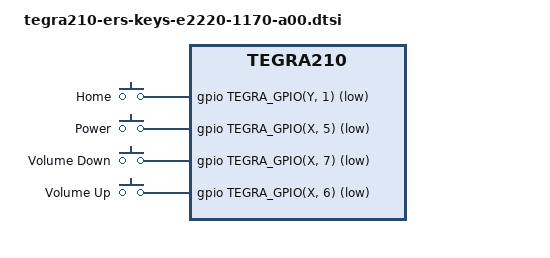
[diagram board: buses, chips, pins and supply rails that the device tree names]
#include <dt-bindings/gpio/tegra-gpio.h>
#include <dt-bindings/input/input.h>

/ {
	gpio-keys {
		compatible = "gpio-keys";
		gpio-keys,name = "gpio-keys";
		home {
			label = "Home";
			gpios = <&gpio TEGRA_GPIO(Y, 1) GPIO_ACTIVE_LOW>;
			linux,code = <KEY_HOME>;
		};

		power {
			label = "Power";
			gpios = <&gpio TEGRA_GPIO(X, 5) GPIO_ACTIVE_LOW>;
			linux,code = <KEY_POWER>;
			gpio-key,wakeup;
		};

		volume_down {
			label = "Volume Down";
			gpios = <&gpio TEGRA_GPIO(X, 7) GPIO_ACTIVE_LOW>;
			linux,code = <KEY_VOLUMEDOWN>;
		};

		volume_up {
			label = "Volume Up";
			gpios = <&gpio TEGRA_GPIO(X, 6) GPIO_ACTIVE_LOW>;
			linux,code = <KEY_VOLUMEUP>;
		};
	};
};
